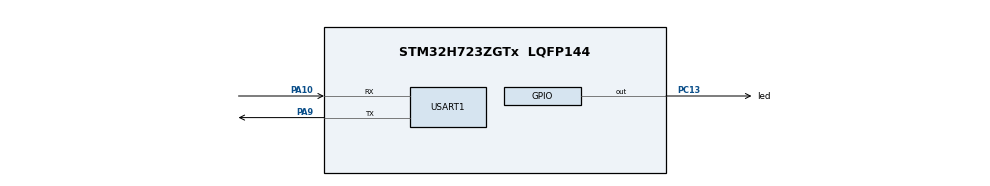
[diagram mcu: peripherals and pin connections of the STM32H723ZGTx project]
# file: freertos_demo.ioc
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FREERTOS.Tasks01=defaultTask,24,128,StartDefaultTask,Default,NULL,Dynamic,NULL,NULL;flash_led,24,128,Start_flash_led,Default,NULL,Dynamic,NULL,NULL;usart1_printf,24,128,Start_usart1_printf,Default,NULL,Dynamic,NULL,NULL
FREERTOS.configUSE_NEWLIB_REENTRANT=1
Mcu.Family=STM32H7
Mcu.Name=STM32H723ZGTx
Mcu.Package=LQFP144
NVIC.PriorityGroup=NVIC_PRIORITYGROUP_4
NVIC.TIM7_IRQn=true\:15\:0\:false\:false\:true\:false\:false\:true\:true
NVIC.TimeBase=TIM7_IRQn
NVIC.TimeBaseIP=TIM7
PA10.Mode=Asynchronous
PA10.Signal=USART1_RX
PA9.Mode=Asynchronous
PA9.Signal=USART1_TX
PC13.GPIO_Label=led
PC13.GPIO_PuPd=GPIO_PULLUP
PC13.Signal=GPIO_Output
PC14-OSC32_IN.Mode=LSE-External-Oscillator
PC14-OSC32_IN.Signal=RCC_OSC32_IN
PC15-OSC32_OUT.Mode=LSE-External-Oscillator
PC15-OSC32_OUT.Signal=RCC_OSC32_OUT
PH0-OSC_IN.Mode=HSE-External-Oscillator
PH0-OSC_IN.Signal=RCC_OSC_IN
PH1-OSC_OUT.Mode=HSE-External-Oscillator
PH1-OSC_OUT.Signal=RCC_OSC_OUT
ProjectManager.HeapSize=0x200
ProjectManager.StackSize=0x400
ProjectManager.TargetToolchain=STM32CubeIDE
RCC.ADCFreq_Value=129000000
RCC.APB1Freq_Value=137500000
RCC.APB2Freq_Value=137500000
RCC.APB3Freq_Value=137500000
RCC.APB4Freq_Value=137500000
RCC.CortexFreq_Value=550000000
RCC.D1PPRE=RCC_APB3_DIV2
RCC.D2PPRE1=RCC_APB1_DIV2
RCC.D2PPRE2=RCC_APB2_DIV2
RCC.D3PPRE=RCC_APB4_DIV2
RCC.DIVM1=4
RCC.DIVN1=34
RCC.DIVP1=1
RCC.HCLKFreq_Value=275000000
RCC.HPRE=RCC_HCLK_DIV2
RCC.PLL2FRACN=0
RCC.PLL3FRACN=0
RCC.PLLFRACN=3072
RCC.SYSCLKFreq_VALUE=550000000
RCC.SYSCLKSource=RCC_SYSCLKSOURCE_PLLCLK
RCC.USBFreq_Value=275000000
USART1.VirtualMode-Asynchronous=VM_ASYNC
VP_DTS_VS-DTS.Mode=DTS
VP_FREERTOS_VS_CMSIS_V2.Mode=CMSIS_V2
VP_SYS_VS_tim7.Mode=TIM7
board=custom

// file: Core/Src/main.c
/* USER CODE BEGIN Header */
/**
  ******************************************************************************
  * @file           : main.c
  * @brief          : Main program body
  ******************************************************************************
  * @attention
  *
  * Copyright (c) 2023 STMicroelectronics.
  * All rights reserved.
  *
  * This software is licensed under terms that can be found in the LICENSE file
  * in the root directory of this software component.
  * If no LICENSE file comes with this software, it is provided AS-IS.
  *
  ******************************************************************************
  */
/* USER CODE END Header */
#include "main.h"
#include "cmsis_os.h"
#include "dts.h"
#include "usart.h"
#include "gpio.h"

/* USER CODE BEGIN Includes */
#include "stdio.h"
/* USER CODE END Includes */

void SystemClock_Config(void);

void MX_FREERTOS_Init(void);

int main(void) {

    /* MCU Configuration--------------------------------------------------------*/

    /* Reset of all peripherals, Initializes the Flash interface and the Systick. */
    HAL_Init();

    /* Configure the system clock */
    SystemClock_Config();

    /* Initialize all configured peripherals */
    MX_GPIO_Init();
    MX_USART1_UART_Init();
    MX_DTS_Init();
    /* USER CODE BEGIN 2 */
    HAL_DTS_Start(&hdts);
    /* USER CODE END 2 */

    /* Init scheduler */
    osKernelInitialize();  /* Call init function for freertos objects (in freertos.c) */
    MX_FREERTOS_Init();

    /* Start scheduler */
    osKernelStart();
    /* We should never get here as control is now taken by the scheduler */
    /* Infinite loop */
    while (1) {

    }
}

void SystemClock_Config(void) {
    RCC_OscInitTypeDef RCC_OscInitStruct = {0};
    RCC_ClkInitTypeDef RCC_ClkInitStruct = {0};

    /** Supply configuration update enable
    */
    HAL_PWREx_ConfigSupply(PWR_LDO_SUPPLY);

    /** Configure the main internal regulator output voltage
    */
    __HAL_PWR_VOLTAGESCALING_CONFIG(PWR_REGULATOR_VOLTAGE_SCALE0);

    while (!__HAL_PWR_GET_FLAG(PWR_FLAG_VOSRDY)) {}

    /** Initializes the RCC Oscillators according to the specified parameters
    * in the RCC_OscInitTypeDef structure.
    */
    RCC_OscInitStruct.OscillatorType = RCC_OSCILLATORTYPE_HSI;
    RCC_OscInitStruct.HSIState = RCC_HSI_DIV1;
    RCC_OscInitStruct.HSICalibrationValue = 64;
    RCC_OscInitStruct.PLL.PLLState = RCC_PLL_ON;
    RCC_OscInitStruct.PLL.PLLSource = RCC_PLLSOURCE_HSI;
    RCC_OscInitStruct.PLL.PLLM = 4;
    RCC_OscInitStruct.PLL.PLLN = 34;
    RCC_OscInitStruct.PLL.PLLP = 1;
    RCC_OscInitStruct.PLL.PLLQ = 2;
    RCC_OscInitStruct.PLL.PLLR = 2;
    RCC_OscInitStruct.PLL.PLLRGE = RCC_PLL1VCIRANGE_3;
    RCC_OscInitStruct.PLL.PLLVCOSEL = RCC_PLL1VCOWIDE;
    RCC_OscInitStruct.PLL.PLLFRACN = 3072;
    if (HAL_RCC_OscConfig(&RCC_OscInitStruct) != HAL_OK) {
        Error_Handler();
    }

    /** Initializes the CPU, AHB and APB buses clocks
    */
    RCC_ClkInitStruct.ClockType = RCC_CLOCKTYPE_HCLK | RCC_CLOCKTYPE_SYSCLK
                                  | RCC_CLOCKTYPE_PCLK1 | RCC_CLOCKTYPE_PCLK2
                                  | RCC_CLOCKTYPE_D3PCLK1 | RCC_CLOCKTYPE_D1PCLK1;
    RCC_ClkInitStruct.SYSCLKSource = RCC_SYSCLKSOURCE_PLLCLK;
    RCC_ClkInitStruct.SYSCLKDivider = RCC_SYSCLK_DIV1;
    RCC_ClkInitStruct.AHBCLKDivider = RCC_HCLK_DIV2;
    RCC_ClkInitStruct.APB3CLKDivider = RCC_APB3_DIV2;
    RCC_ClkInitStruct.APB1CLKDivider = RCC_APB1_DIV2;
    RCC_ClkInitStruct.APB2CLKDivider = RCC_APB2_DIV2;
    RCC_ClkInitStruct.APB4CLKDivider = RCC_APB4_DIV2;

    if (HAL_RCC_ClockConfig(&RCC_ClkInitStruct, FLASH_LATENCY_3) != HAL_OK) {
        Error_Handler();
    }
}

void HAL_TIM_PeriodElapsedCallback(TIM_HandleTypeDef *htim) {
    if (htim->Instance == TIM7) {
        HAL_IncTick();
    }
}

void Error_Handler(void) {
    __disable_irq();
    while (1) {
    }
}

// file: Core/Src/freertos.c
/* USER CODE BEGIN Header */
/**
  ******************************************************************************
  * File Name          : freertos.c
  * Description        : Code for freertos applications
  ******************************************************************************
  * @attention
  *
  * Copyright (c) 2023 STMicroelectronics.
  * All rights reserved.
  *
  * This software is licensed under terms that can be found in the LICENSE file
  * in the root directory of this software component.
  * If no LICENSE file comes with this software, it is provided AS-IS.
  *
  ******************************************************************************
  */
/* USER CODE END Header */

#include "FreeRTOS.h"
#include "task.h"
#include "main.h"
#include "cmsis_os.h"

/* USER CODE BEGIN Includes */
#include "stdio.h"
#include "dts.h"
/* USER CODE END Includes */

/* USER CODE BEGIN Variables */
static int32_t temperature;
/* USER CODE END Variables */
/* Definitions for defaultTask */
osThreadId_t defaultTaskHandle;
const osThreadAttr_t defaultTask_attributes = {
  .name = "defaultTask",
  .stack_size = 128 * 4,
  .priority = (osPriority_t) osPriorityNormal,
};
/* Definitions for flash_led */
osThreadId_t flash_ledHandle;
const osThreadAttr_t flash_led_attributes = {
  .name = "flash_led",
  .stack_size = 128 * 4,
  .priority = (osPriority_t) osPriorityNormal,
};
/* Definitions for usart1_printf */
osThreadId_t usart1_printfHandle;
const osThreadAttr_t usart1_printf_attributes = {
  .name = "usart1_printf",
  .stack_size = 128 * 4,
  .priority = (osPriority_t) osPriorityNormal,
};

void StartDefaultTask(void *argument);
void Start_flash_led(void *argument);
void Start_usart1_printf(void *argument);

void MX_FREERTOS_Init(void); /* (MISRA C 2004 rule 8.1) */

void MX_FREERTOS_Init(void) {

  /* Create the thread(s) */
  /* creation of defaultTask */
  defaultTaskHandle = osThreadNew(StartDefaultTask, NULL, &defaultTask_attributes);

  /* creation of flash_led */
  flash_ledHandle = osThreadNew(Start_flash_led, NULL, &flash_led_attributes);

  /* creation of usart1_printf */
  usart1_printfHandle = osThreadNew(Start_usart1_printf, NULL, &usart1_printf_attributes);

}

void StartDefaultTask(void *argument)
{
    for (;;) {
        osDelay(1);
    }
}

void Start_flash_led(void *argument)
{
  /* USER CODE BEGIN Start_flash_led */
    /* Infinite loop */
    for (;;) {
        HAL_GPIO_TogglePin(led_GPIO_Port,led_Pin);
        osDelay(500);
    }
  /* USER CODE END Start_flash_led */
}

void Start_usart1_printf(void *argument)
{
  /* USER CODE BEGIN Start_usart1_printf */
    /* Infinite loop */
    for (;;) {
        HAL_DTS_GetTemperature(&hdts,&temperature);
        printf("CPU Temperature : %d °C\r\n",temperature);
        osDelay(20);
    }
  /* USER CODE END Start_usart1_printf */
}
